# AE612FA0E5597LS0_CM55_HP_View register map
Vendor: Alif Semiconductor; Series: E6; File version: 1.0
CPU: CM55 r1p0, selectable endian, MPU, FPU, double-precision FPU, DSP, VTOR, 8 interrupt priority bits, 1 SAU regions
Registers are 32-bit, read-write, reset 0x0 unless marked. A register's access mark holds for its fields unless they carry their own. Offsets are from the block's base; [hi:lo] are bit positions; {n}, {i} and the like mark numbered series; 'fields as' and 'values as' point back to an identical list.

## ADC120
Base 0x49020000
Same registers: ADC121 0x49021000, ADC122 0x49022000, ADC24 0x49027000
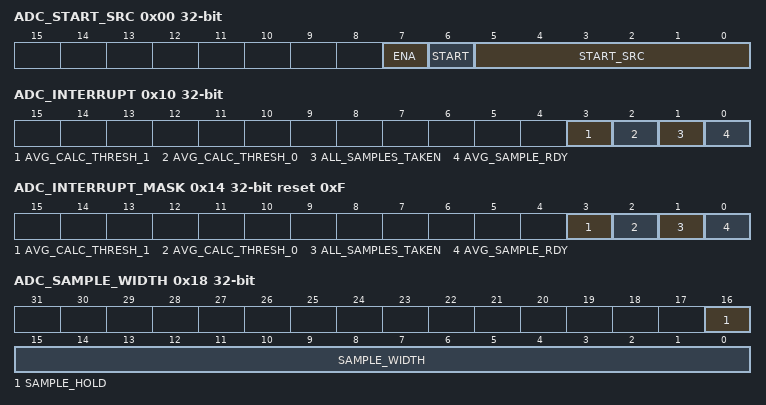
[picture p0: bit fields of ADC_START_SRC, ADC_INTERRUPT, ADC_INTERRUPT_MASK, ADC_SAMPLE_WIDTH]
0x00 ADC_START_SRC — ADC Start-of-Conversion Source Register
  [7] ENA — When this bit is set to 1, the ADC_CONTROL register is enabled to start the processing.
  [6] START — When this bit is set to 1, the ADC starts/continues its operation. This is used to enable functions by software, without using the event inputs.
  [5:0] START_SRC — This bit field enables the corresponding event input to the ADC to start (and continue, if active) the ADC. Once the number samples programmed in ADC_AVG_NUM is reached, if one of the enabled event inputs is active, the ADC functionality continues. If not, it stops.
0x04 ADC_COMP_THRESH_A — ADC Comparator Threshold A Register
  [31:0] COMP_THRESHOLD_A — Comparison threshold A value. Used for interrupt generation. The programmed value should be equal to the desired threshold multiplied by the number of samples set in ADC_AVG_NUM.
0x08 ADC_COMP_THRESH_B — ADC Comparator Threshold B Register
  [31:0] COMP_THRESHOLD_B — Comparison threshold B value. Used for interrupt generation. The programmed value should be equal to the desired threshold multiplied by the number of samples set in ADC_AVG_NUM.
0x0C ADC_CLK_DIVISOR reset 0x2 — ADC Clock Divider Value Register
  [9:0] CLK_DIVISOR — Clock divider applied to input clock (ADC_CLK): Others: Reserved
    2=Divide by 2; 3=Divide by 3; 16=Divide by 16
0x10 ADC_INTERRUPT — ADC Interrupt Status and Clear Register
  [3] AVG_CALC_THRESH_1 write-1-clears — Status and clear for CMPB interrupt. Read 1: A threshold passed depending on ADC_CONTROL[INT_CTRL] register field. Write 1 to clear.
  [2] AVG_CALC_THRESH_0 write-1-clears — Status and clear for CMPA interrupt. Read 1: A threshold passed depending on ADC_CONTROL[INT_CTRL] register field. Write 1 to clear.
  [1] ALL_SAMPLES_TAKEN write-1-clears — Status and clear for DONE1 interrupt. Read 1: All samples taken. Data collection has now stopped with the final loading of a ADC_SAMPLE_REG_n register, due to either turning off ADC_START_SRC[START] for continuous operation, or ADC_CONTROL[START] one-time run has finished, or windowing event is no longer active. Write 1 to clear.
  [0] AVG_SAMPLE_RDY write-1-clears — Status and clear for DONE0 interrupt. Read 1: Analog logic has delivered the number of samples set in the ADC_AVG_NUM register, indicating that the current ADC_SAMPLE_REG_n has been loaded. Write 1 to clear.
0x14 ADC_INTERRUPT_MASK reset 0xF
  [3] AVG_CALC_THRESH_1 — Mask for CMPB interrupt.
  [2] AVG_CALC_THRESH_0 — Mask for CMPA interrupt.
  [1] ALL_SAMPLES_TAKEN — Mask for DONE1 interrupt.
  [0] AVG_SAMPLE_RDY — Mask for DONE0 interrupt.
0x18 ADC_SAMPLE_WIDTH — ADC Sampling Signal Duration Register
  [16] SAMPLE_HOLD — Used in ADC24. If 1, the Sample signal is continuously active while gathering data.
  [15:0] SAMPLE_WIDTH — Duration of the Sample signal to ADC analog frond-end in PCLK clocks. Valid values are 2 to 32.
0x20 ADC_AVG_NUM — ADC Number of Samples for Averaging Register
  [31:0] AVG_NUM — Program up to 256 number of samples to collect. The result is loaded into the sample registers (ADC_SAMPLE_REG_n). The programmed value must be a power of 2. The minimum supported value is: 2 for ADC12, 1 for ADC24.
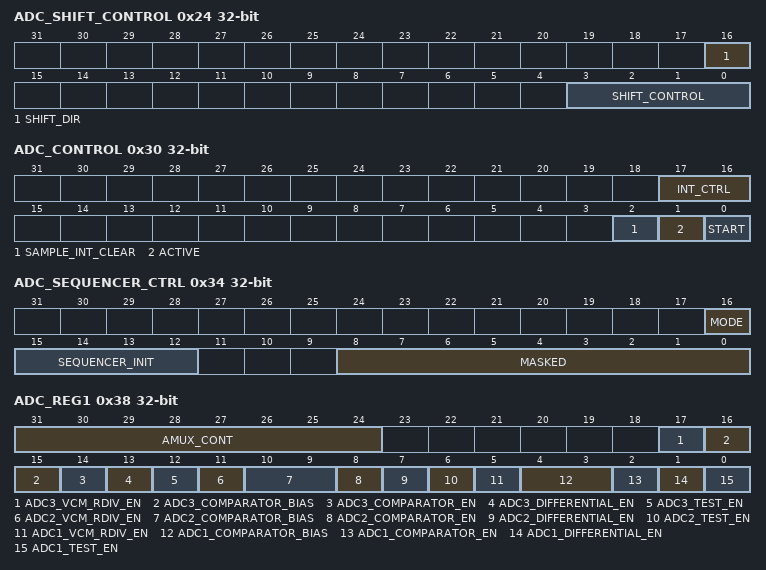
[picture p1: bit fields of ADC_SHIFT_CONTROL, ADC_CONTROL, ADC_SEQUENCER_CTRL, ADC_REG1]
0x24 ADC_SHIFT_CONTROL — ADC Data Shift Select Register
  [16] SHIFT_DIR — Shift averaged value before loading into the sample registers (ADC_SAMPLE_REG_n):
    0=Shift averaged value left; 1=Shift averaged value right
  [3:0] SHIFT_CONTROL — Shift these bits before loading value into the sample registers (ADC_SAMPLE_REG_n). To calculate the sample average, program this bit field with the number of bits to shift right based upon the number of samples taken: 1 sample: no shift 2 samples: shift right 1 bit 4 samples: shift right 2 bits 256 samples: shift right 8 bits If any additional shift left or right is desired it should be added to or subtracted from the averaging shift above, and the resulting value programmed into this register.
0x30 ADC_CONTROL — ADC Single-shot Conversion Start and Comparator Threshold Mode Register
  [17:16] INT_CTRL — This field specifies the threshold windows for CMPA and CMPB interrupt generation.
    0=CMPA = Above threshold A value; CMPB = Above threshold B value; 1=CMPA = Below threshold A value; CMPB = Below threshold B value; 2=CMPA = Between threshold A and B values; CMPB = Outside threshold A and B values
  [2] SAMPLE_INT_CLEAR — If set, enables mode where reading any ADC_SAMPLE_REG_n will clear all active interrupts.
  [1] ACTIVE ro — If 1, indicates ADC is processing data.
  [0] START wo — Write 1: Starts the ADC process. This is one-time start control. If the number of programmed samples is reached, processing stops, unless another event causes it to continue. For START bit to be operational the ADC_START_SRC[ENA] must be 1.
0x34 ADC_SEQUENCER_CTRL — ADC Sequencer Control Register
  [16] MODE — Sequencer mode:
    0=Sequencer loops over all 9 analog inputs, while skipping masked inputs (set in the MASKED bit field). For ADC24, it loops over the lower 4 inputs.; 1=Sequencer is fixed at SEQUENCER_INIT field value
  [15:12] SEQUENCER_INIT — Initial value (analog input index) of sequencer to use when started. This must be set to an unmasked input.
  [8:0] MASKED — Masked analog inputs are skipped when advancing the sequencer. Each bit corresponds to an analog input. Set a bit to 1 to mask the corresponding input. For ADC24, only the lower 4 inputs are used; the upper 5 inputs are automatically masked.
0x38 ADC_REG1 — ADC Analog Control Register for ADC12 Modules
  [31:24] AMUX_CONT — Analog test mux control (external to ADC12). Bit 31 is a master enable (set to 1 to enable AMUX). Upper 4 bits determine mux section [30:27]. Lower 3 bits select mux input [26:24]. Default = 0x0
  [17] ADC3_VCM_RDIV_EN — Enable ADC122 resistive divider:
    0=The resistive divider is off, common mode is not well defined; 1=The resistive divider is on, common mode is VDD/2
  [16:15] ADC3_COMPARATOR_BIAS — ADC122 comparator biasing:
    0=0.5 MS/s (Power optmization with lower sample rate); 1=1 MS/s; 2=2.5 MS/s; 3=5 MS/s
  [14] ADC3_COMPARATOR_EN — Enable ADC122 comparator:
    0=Comparator is off; 1=Comparator is enabled
  [13] ADC3_DIFFERENTIAL_EN — Enable ADC122 differential mode:
    0=IN0, IN1, IN2, IN3, IN4, and IN5 are single-ended inputs; 1=IN0/IN1, IN2/IN3, and IN4/IN5 make 3 differential inputs
  [12] ADC3_TEST_EN — Enable ADC122 test signal to go to the test MUX:
    0=Disabled; 1=Enabled
  [11] ADC2_VCM_RDIV_EN — Enable ADC121 resistive divider:
    values as ADC3_VCM_RDIV_EN
  [10:9] ADC2_COMPARATOR_BIAS — ADC121 comparator biasing:
    values as ADC3_COMPARATOR_BIAS
  [8] ADC2_COMPARATOR_EN — Enable ADC121 comparator:
    0=Comparator is off; 1=Comparator is enabled
  [7] ADC2_DIFFERENTIAL_EN — Enable ADC121 differential mode:
    values as ADC3_DIFFERENTIAL_EN
  [6] ADC2_TEST_EN — Enable ADC121 test signal to go to the test MUX:
    0=Disabled; 1=Enabled
  [5] ADC1_VCM_RDIV_EN — Enable ADC121 resistive divider:
    values as ADC3_VCM_RDIV_EN
  [4:3] ADC1_COMPARATOR_BIAS — ADC120 comparator biasing:
    values as ADC3_COMPARATOR_BIAS
  [2] ADC1_COMPARATOR_EN — Enable ADC120 comparator:
    0=Comparator is off; 1=Comparator is enabled
  [1] ADC1_DIFFERENTIAL_EN — Enable ADC120 differential mode:
    values as ADC3_DIFFERENTIAL_EN
  [0] ADC1_TEST_EN — Enable ADC120 test signal to go to the test MUX:
    0=Disabled; 1=Enabled
0x3C ADC_SEL ro — ADC Sample Register Selected (read-only value of n)
  [3:0] SAMPLE_REG_NUM — Indicates the current ADC_SAMPLE_REG_n number to be loaded with an ADC result.
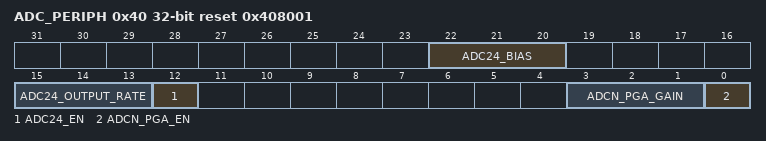
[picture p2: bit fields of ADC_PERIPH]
0x40 ADC_PERIPH reset 0x408001 — ADC Peripheral Register
  [22:20] ADC24_BIAS — ADC24 bias control. This field is functional only for ADC24.
  [15:13] ADC24_OUTPUT_RATE — ADC24 output rate select: Other values should not be used. This field is functional only for ADC24.
    0=Val_0b000 (1 kS/s); 1=Val_0b001 (2 kS/s); 2=Val_0b010 (4 kS/s); 3=Val_0b011 (8 kS/s); 4=Val_0b100 (16 kS/s)
  [12] ADC24_EN — ADC24 enable. This bit is functional only for ADC24.
    0=Disabled; 1=Enabled
  [3:1] ADCN_PGA_GAIN — ADCn PGA gain value select. For ADC12, this field has the following valid values: 0x0: 4 dB 0x1: 8 dB 0x4: 12 dB 0x5: 16 dB 0x6: 20 dB Other values should not be used. For ADC24, this field has the following valid values: 0x0: Do not use 0x1: 6 dB 0x2: 12 dB 0x3: 18 dB 0x4: 24 dB 0x5: 30 dB 0x6: 36 dB 0x7: 42 dB Depending on the ADC module, this field is named as follows: - ADC1_PGA_GAIN for ADC120; - ADC2_PGA_GAIN for ADC121; - ADC3_PGA_GAIN for ADC122; - ADC24_PGA_GAIN for ADC24;
  [0] ADCN_PGA_EN — ADCn PGA enable. Note: ADC12 must be put into differential mode when PGA is enabled. Depending on the ADC module, this bit is named as follows: - ADC1_PGA_EN for ADC120; - ADC2_PGA_EN for ADC121; - ADC3_PGA_EN for ADC122; - ADC24_PGA_EN for ADC24;
    0=Disabled; 1=Enabled
{0x50+4i} ADC_SAMPLE_REG_[{i}] (i=0..8) — ADC Sampled Value From Input n Register
  [31:0] VALUE — Result of ADC operation on input n.
